# ADuCM320i register map
Vendor: Analog Devices Inc.; Series: ARMCM3; File version: 1.0
CPU: CM3 r2p1, little endian, no MPU, no FPU, 3 interrupt priority bits
Registers are 16-bit, read-write, no defined reset value unless marked. A register's access mark holds for its fields unless they carry their own. Offsets are from the block's base; [hi:lo] are bit positions.

## UART
Base 0x40005000
0x00 COMTX wo read-modifies — Transmit holding register
  [7:0] THR range 0x00000000..0x000000FF — Transmit Holding Register
0x00 COMRX ro read-modifies (alternate view of COMTX) — Receive buffer register
  [7:0] RBR range 0x00000000..0x000000FF — Receive Buffer Register
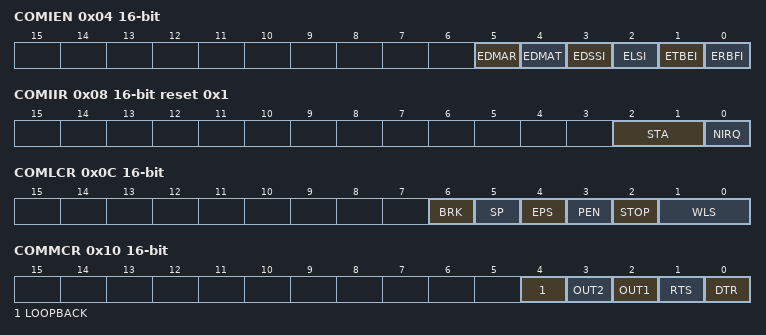
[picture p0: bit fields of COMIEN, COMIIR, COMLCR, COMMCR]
0x04 COMIEN — Interrupt enable register
  [5] EDMAR — DMA requests in receive mode
    0=DIS (DMA requests disabled); 1=EN (DMA requests enabled)
  [4] EDMAT — DMA requests in transmit mode
    0=DIS (DMA requests are disabled); 1=EN (DMA requests are enabled)
  [3] EDSSI — Modem status interrupt
    0=DIS (Interrupt disabled); 1=EN (Interrupt enabled)
  [2] ELSI — Rx status interrupt
    0=DIS (Interrupt disabled); 1=EN (Interrupt enabled)
  [1] ETBEI — Transmit buffer empty interrupt
    0=DIS (Interrupt disabled); 1=EN (Interrupt enabled)
  [0] ERBFI — Receive buffer full interrupt
    0=DIS (Interrupt disabled); 1=EN (Interrupt enabled)
0x08 COMIIR ro reset 0x1 (reset mask 0x0) — Interrupt identification register
  [2:1] STA — Interrupt status
    0=MODEMSTATUS (Modem status interrupt (Read COMMSR to clear)); 1=TXBUFEMPTY (Transmit buffer empty interrupt (Write to COMTX or read COMIIR to clear)); 2=RXBUFFULL (Receive buffer full interrupt (Read COMRX to clear)); 3=RXLINESTATUS (Receive line status interrupt (Read COMLSR to clear))
  [0] NIRQ — Interrupt flag
    0=CLR (Interrupt occurred. Source of interrupt indicated in the STA bits.); 1=SET (No interrupt occurred.)
0x0C COMLCR — Line control register
  [6] BRK — Set Break
    0=DIS (Force TxD to 0); 1=EN (Normal TxD operation)
  [5] SP — Stick Parity
    0=DIS (Parity will not be forced based on EPS and PEN); 1=EN (Parity forced based on EPS and PEN)
  [4] EPS — Parity Select
    0=ODD (Odd parity will be transmitted and checked); 1=EVEN (Even parity will be transmitted and checked)
  [3] PEN — Parity Enable
    0=DIS (Parity will not be transmitted or checked); 1=EN (Parity will be transmitted and checked)
  [2] STOP — Stop Bit
    0=DIS (Send 1 stop bit regardless of the word length (WLS).); 1=EN (Send a number of stop bits based on the word length. Transmit 1.5 stop bits if the word length is 5 bits (WLS = 00), or 2 stop bits if the word length is 6 (WLS = 01), 7 (WLS = 10), or 8 bits (WLS = 11).)
  [1:0] WLS — Word Length Select
    0=FIVEBITS (5 bits); 1=SIXBITS (6 bits); 2=SEVENBITS (7 bits); 3=EIGHTBITS (8 bits)
0x10 COMMCR — Modem control register
  [4] LOOPBACK — Loopback mode
    0=DIS (Normal operation - loopback disabled); 1=EN (Loopback enabled)
  [3] OUT2 — Output 2
    0=HIGH (Force OUT2 to a logic 1); 1=LOW (Force OUT2 to a logic 0)
  [2] OUT1 — Output 1
    0=HIGH (Force OUT1 to a logic 1); 1=LOW (Force OUT1 to a logic 0)
  [1] RTS — Request to send
    0=HIGH (Force RTS to a logic 1); 1=LOW (Force RTS to a logic 0)
  [0] DTR — Data Terminal Ready
    0=HIGH (Force DTR to a logic 1); 1=LOW (Force DTR to a logic 0)
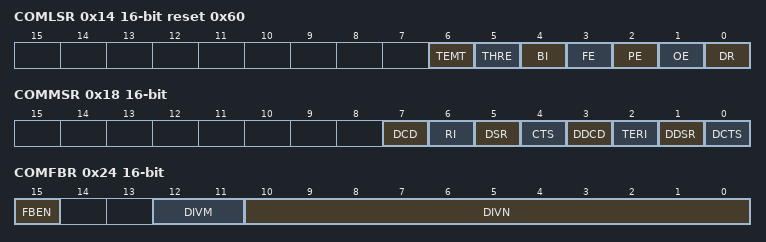
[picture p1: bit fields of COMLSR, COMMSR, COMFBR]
0x14 COMLSR ro reset 0x60 (reset mask 0x0) — Line status register
  [6] TEMT — COMTX and shift register empty status
    0=CLR (COMTX has been written to and contains data to be transmitted. Care should be taken not to overwrite its value.); 1=SET (COMTX and the transmit shift register are empty and it is safe to write new data to COMTX. Data has been transmitted.)
  [5] THRE — COMTX empty
    0=CLR (COMTX has been written to and contains data to be transmitted. Care should be taken not to overwrite its value.); 1=SET (COMTX is empty and it is safe to write new data to COMTX. The previous data may not have been transmitted yet and can still be present in the shift register.)
  [4] BI — Break indicator
    0=CLR (SIN was not detected to be longer than the maximum word length.); 1=SET (SIN was held low for more than the maximum word length.)
  [3] FE — Framing error
    0=CLR (No invalid Stop bit was detected.); 1=SET (An invalid Stop bit was detected on a received word.)
  [2] PE — Parity error
    0=CLR (No parity error was detected); 1=SET (A parity error occurred on a received word.)
  [1] OE — Overrun error
    0=CLR (Receive data has not been overwritten); 1=SET (Receive data was overwritten by new data before COMRX was read.)
  [0] DR — Data ready
    0=CLR (COMRX does not contain new receive data.); 1=SET (COMRX contains receive data that should be read.)
0x18 COMMSR ro — Modem status register
  [7] DCD — Data Carrier Detect
    0=DIS (DCD is currently logic high); 1=EN (DCD is currently logic low)
  [6] RI — Ring Indicator
    0=DIS (RI is currently logic high); 1=EN (RI is currently logic low)
  [5] DSR — Data Set Ready
    0=DIS (DSR is currently logic high); 1=EN (DSR is currently logic low)
  [4] CTS — Clear To Send
    0=DIS (CTS is currently logic high); 1=EN (CTS is currently logic low)
  [3] DDCD — Delta DCD
    0=DIS (DCD has not changed state since COMMSR was last read); 1=EN (DCD changed state since COMMSR last read)
  [2] TERI — Trailing Edge RI
    0=DIS (RI has not changed from 0 to 1 since COMMSR last read); 1=EN (RI changed from 0 to 1 since COMMSR last read)
  [1] DDSR — Delta DSR
    0=DIS (DSR has not changed state since COMMSR was last read); 1=EN (DSR changed state since COMMSR last read)
  [0] DCTS — Delta CTS
    0=DIS (CTS has not changed state since COMMSR was last read); 1=EN (CTS changed state since COMMSR last read)
0x1C COMSCR — Scratch buffer register
  [7:0] SCR range 0x00000000..0x000000FF — Scratch
0x24 COMFBR — Fractional baud rate register
  [15] FBEN range 0x00000000..0x00000001 — Fractional baud rate generator enable
  [12:11] DIVM range 0x00000000..0x00000003 — Fractional baud rate M divide bits 1 to 3
  [10:0] DIVN range 0x00000000..0x000007FF — Fractional baud rate N divide bits 0 to 2047.
0x28 COMDIV reset 0x1 (reset mask 0x0) — Baud rate divider register
  [15:0] DIV range 0x00000000..0x0000FFFF — Baud rate divider
